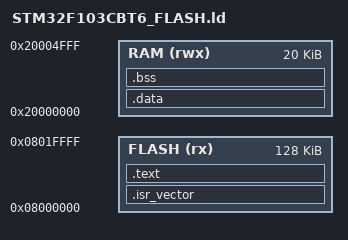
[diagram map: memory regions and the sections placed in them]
ENTRY(Reset_Handler)
USB     = 0x40005C00;
USB_PMA = 0x40006000;
_estack = ORIGIN(RAM) + LENGTH(RAM);

MEMORY
{
  FLASH (rx)  : ORIGIN = 0x08000000, LENGTH = 128K
  RAM   (rwx) : ORIGIN = 0x20000000, LENGTH = 20K
}

SECTIONS
{
  .isr_vector : { . = ALIGN(4); KEEP(*(.isr_vector)) . = ALIGN(4); } > FLASH
  .text :
  {
    . = ALIGN(4);
    *(.text .text.*)
    *(.rodata .rodata.*)
    KEEP(*(.init))
    KEEP(*(.fini))
    . = ALIGN(4);
    _etext = .;
  } > FLASH

  _sidata = LOADADDR(.data);
  .data : AT(_etext)
  {
    . = ALIGN(4);
    _sdata = .;
    *(.data .data.*)
    . = ALIGN(4);
    _edata = .;
  } > RAM

  .bss (NOLOAD) :
  {
    . = ALIGN(4);
    _sbss = .;
    *(.bss .bss.*)
    *(COMMON)
    . = ALIGN(4);
    _ebss = .;
  } > RAM

  /DISCARD/ : { *(.ARM.exidx*) *(.ARM.extab*) }
}
